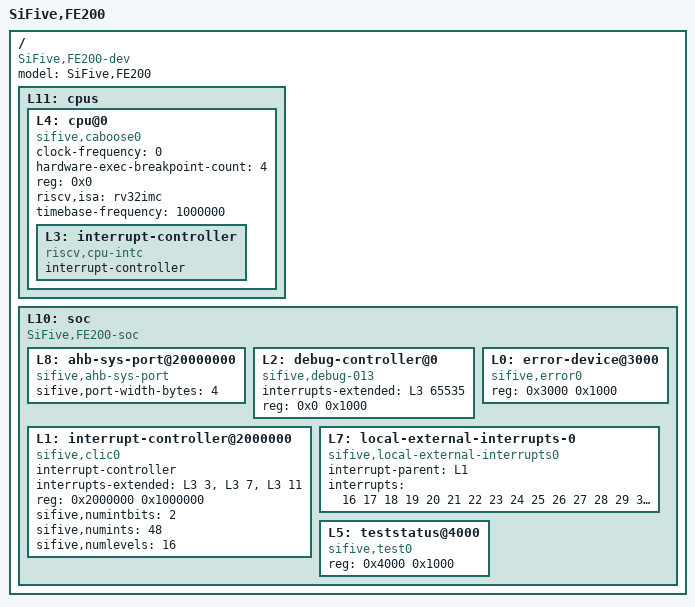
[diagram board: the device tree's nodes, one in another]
/dts-v1/;

/ {
	#address-cells = <1>;
	#size-cells = <1>;
	compatible = "SiFive,FE200-dev", "fe200-dev", "sifive-dev";
	model = "SiFive,FE200";
	L11: cpus {
		#address-cells = <1>;
		#size-cells = <0>;
		L4: cpu@0 {
			clock-frequency = <0>;
			compatible = "sifive,caboose0", "riscv";
			device_type = "cpu";
			hardware-exec-breakpoint-count = <4>;
			reg = <0x0>;
			riscv,isa = "rv32imc";
			status = "okay";
			timebase-frequency = <1000000>;
			L3: interrupt-controller {
				#interrupt-cells = <1>;
				compatible = "riscv,cpu-intc";
				interrupt-controller;
			};
		};
	};
	L10: soc {
		#address-cells = <1>;
		#size-cells = <1>;
		compatible = "SiFive,FE200-soc", "fe200-soc", "sifive-soc", "simple-bus";
		ranges;
		L8: ahb-sys-port@20000000 {
			#address-cells = <1>;
			#size-cells = <1>;
			compatible = "sifive,ahb-sys-port", "sifive,ahb-port", "sifive,sys-port", "simple-external-bus", "simple-bus";
			ranges = <0x20000000 0x20000000 0x20000000>;
			sifive,port-width-bytes = <4>;
		};
		L2: debug-controller@0 {
			compatible = "sifive,debug-013", "riscv,debug-013";
			interrupts-extended = <&L3 65535>;
			reg = <0x0 0x1000>;
			reg-names = "control";
		};
		L0: error-device@3000 {
			compatible = "sifive,error0";
			reg = <0x3000 0x1000>;
		};
		L1: interrupt-controller@2000000 {
			#interrupt-cells = <1>;
			compatible = "sifive,clic0";
			interrupt-controller;
			interrupts-extended = <&L3 3 &L3 7 &L3 11>;
			reg = <0x2000000 0x1000000>;
			reg-names = "control";
			sifive,numintbits = <2>;
			sifive,numints = <48>;
			sifive,numlevels = <16>;
		};
		L7: local-external-interrupts-0 {
			compatible = "sifive,local-external-interrupts0";
			interrupt-parent = <&L1>;
			interrupts = <16 17 18 19 20 21 22 23 24 25 26 27 28 29 30 31 32 33 34 35 36 37 38 39 40 41 42 43 44 45 46 47>;
		};
		L5: teststatus@4000 {
			compatible = "sifive,test0";
			reg = <0x4000 0x1000>;
			reg-names = "control";
		};
	};
};
